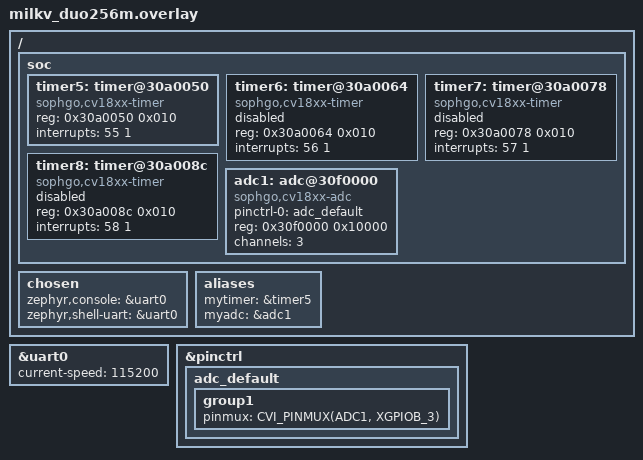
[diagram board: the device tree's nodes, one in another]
/ {
	soc {

		timer5: timer@30a0050 {
			compatible = "sophgo,cv18xx-timer";
			reg = <0x30a0050 0x010>;
			interrupts = <55 1>; 
			status = "okay";
		};

		timer6: timer@30a0064 {
			compatible = "sophgo,cv18xx-timer";
			reg = <0x30a0064 0x010>;
			interrupts = <56 1>; 
			status = "disabled";
		};

		timer7: timer@30a0078 {
			compatible = "sophgo,cv18xx-timer";
			reg = <0x30a0078 0x010>;
			interrupts = <57 1>; 
			status = "disabled";
		};

		timer8: timer@30a008c {
			compatible = "sophgo,cv18xx-timer";
			reg = <0x30a008c 0x010>;
			interrupts = <58 1>; 
			status = "disabled";
		};


		adc1: adc@30f0000 {
			compatible = "sophgo,cv18xx-adc";
			pinctrl-0 = <&adc_default>;
			pinctrl-names = "default";
			reg = <0x30f0000 0x10000>;
			channels = <3>;
			status = "okay";
		};
	};

        chosen {
                zephyr,console = &uart0;
                zephyr,shell-uart = &uart0;
        };

	aliases {
		mytimer = &timer5;
		myadc = &adc1;
	};
};

&uart0 {
        status = "okay";
        current-speed = <115200>;
};

&pinctrl {
	adc_default: adc_default {
		group1 {
			pinmux = <CVI_PINMUX(ADC1, XGPIOB_3)>;
		};
	};
};

